# ATmega32C1 device description
Architecture: AVR8; Family: megaAVR
Registers are 8-bit, access not given, no defined reset value unless marked. A register's access mark holds for its fields unless they carry their own. Offsets are from the block's base; [hi:lo] are bit positions; {n}, {i} and the like mark numbered series.

## ADC — Analog-to-Digital Converter
Instances: ADC 0x00
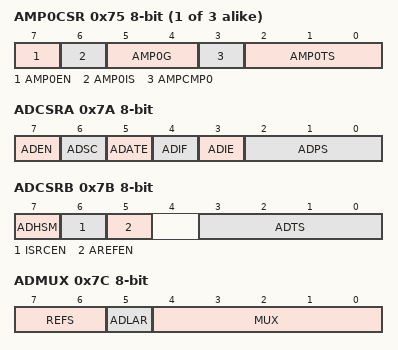
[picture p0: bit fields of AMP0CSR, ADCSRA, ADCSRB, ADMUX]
{0x75+i} AMP{i}CSR (i=0..2)
  [7] AMP{i}EN
  [6] AMP{i}IS
  [5:4] AMP{i}G
  [3] AMPCMP{i} — Amplifier {i} - Comparator {i} Connection
  [2:0] AMP{i}TS
0x78 ADC 16-bit — ADC Data Register Bytes
  [9:0] ADC — ADC Data bits
0x7A ADCSRA — The ADC Control and Status register
  [7] ADEN — ADC Enable
  [6] ADSC — ADC Start Conversion
  [5] ADATE — ADC Auto Trigger Enable
  [4] ADIF — ADC Interrupt Flag
  [3] ADIE — ADC Interrupt Enable
  [2:0] ADPS — ADC Prescaler Select Bits
0x7B ADCSRB — ADC Control and Status Register B
  [7] ADHSM — ADC High Speed Mode
  [6] ISRCEN — Current Source Enable
  [5] AREFEN — Analog Reference pin Enable
  [3:0] ADTS — ADC Auto Trigger Sources
    0=Free Running mode; 1=Analog Comparator; 2=External Interrupt Request 0; 3=Timer/Counter0 Compare Match A; 4=Timer/Counter0 Overflow; 5=Timer/Counter1 Compare Match B; 6=Timer/Counter1 Overflow; 7=Timer/Counter1 Capture Event; 8=PSC0ASY Event; 9=PSC1ASY Event; 10=PSC2ASY Event; 11=Analog comparator 1; 12=Analog comparator 2
0x7C ADMUX — The ADC multiplexer Selection Register
  [7:6] REFS — Reference Selection Bits
    0=AREF, Internal Vref turned off; 1=AVCC with external capacitor at AREF pin; 3=Internal 2.56V Voltage Reference with external capacitor at AREF pin
  [5] ADLAR — Left Adjust Result
  [4:0] MUX — Analog Channel and Gain Selection Bits
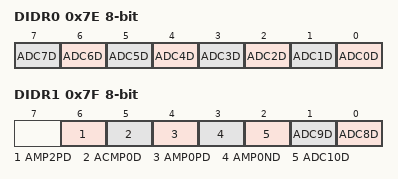
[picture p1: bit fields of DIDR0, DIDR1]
0x7E DIDR0 — Digital Input Disable Register 0
  [n] ADC{n}D (n=0..7) — ADC{n} Digital input Disable
0x7F DIDR1 — Digital Input Disable Register 0
  [6] AMP2PD — AMP2P Pin Digital input Disable
  [5] ACMP0D — ACMP0 Pin Digital input Disable
  [4] AMP0PD — AMP0P Pin Digital input Disable
  [3] AMP0ND — AMP0N Pin Digital input Disable
  [2] ADC10D — ADC10 Pin Digital input Disable
  [1] ADC9D — ADC9 Pin Digital input Disable
  [0] ADC8D — ADC8 Pin Digital input Disable
Value list ANALOG_ADC_MUXPOS: {v}=ADC{v} (ADC input pin {v}) (v=0..10); 11=TEMPSENSE (Temperature sensor); 12=VCC4 (Internal VCC / 4); 13=ISRC (Current source); 14=AMP0 (Analog Differential Amplifier 0); 15=AMP1 (Analog Differential Amplifier 1); 16=AMP2 (Analog Differential Amplifier 2); 17=BNDGAP (Bandgap); 18=GND (0V (GND))

## LINUART — Local Interconnect Network
Instances: LINUART 0x00
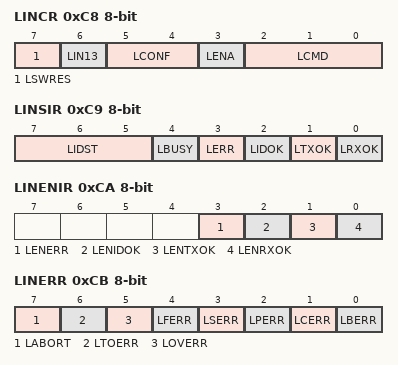
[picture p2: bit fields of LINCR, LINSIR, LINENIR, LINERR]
0xC8 LINCR — LIN Control Register
  [7] LSWRES — Software Reset
  [6] LIN13 — LIN Standard
  [5:4] LCONF — LIN Configuration bits
  [3] LENA — LIN or UART Enable
  [2:0] LCMD — LIN Command and Mode bits
0xC9 LINSIR — LIN Status and Interrupt Register
  [7:5] LIDST — Identifier Status bits
  [4] LBUSY — Busy Signal
  [3] LERR — Error Interrupt
  [2] LIDOK — Identifier Interrupt
  [1] LTXOK — Transmit Performed Interrupt
  [0] LRXOK — Receive Performed Interrupt
0xCA LINENIR — LIN Enable Interrupt Register
  [3] LENERR — Enable Error Interrupt
  [2] LENIDOK — Enable Identifier Interrupt
  [1] LENTXOK — Enable Transmit Performed Interrupt
  [0] LENRXOK — Enable Receive Performed Interrupt
0xCB LINERR — LIN Error Register
  [7] LABORT — Abort Flag
  [6] LTOERR — Frame Time Out Error Flag
  [5] LOVERR — Overrun Error Flag
  [4] LFERR — Framing Error Flag
  [3] LSERR — Synchronization Error Flag
  [2] LPERR — Parity Error Flag
  [1] LCERR — Checksum Error Flag
  [0] LBERR — Bit Error Flag
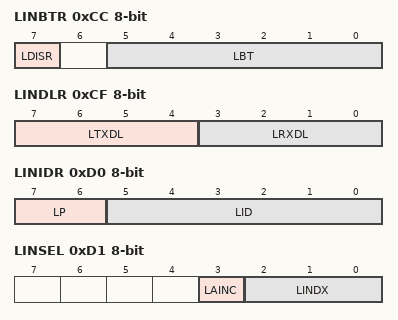
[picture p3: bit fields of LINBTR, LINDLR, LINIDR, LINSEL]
0xCC LINBTR — LIN Bit Timing Register
  [7] LDISR — Disable Bit Timing Resynchronization
  [5:0] LBT — LIN Bit Timing bits
0xCD LINBRR 16-bit — LIN Baud Rate Register
  [11:0] LDIV
0xCF LINDLR — LIN Data Length Register
  [7:4] LTXDL — LIN Transmit Data Length bits
  [3:0] LRXDL — LIN Receive Data Length bits
0xD0 LINIDR — LIN Identifier Register
  [7:6] LP — Parity bits
  [5:0] LID — Identifier bit 5 or Data Length bits
0xD1 LINSEL — LIN Data Buffer Selection Register
  [3] LAINC — Auto Increment of Data Buffer Index (Active Low)
  [2:0] LINDX — FIFO LIN Data Buffer Index bits
0xD2 LINDAT — LIN Data Register
  [7:0] LDATA

## SPI — Serial Peripheral Interface
Instances: SPI 0x00
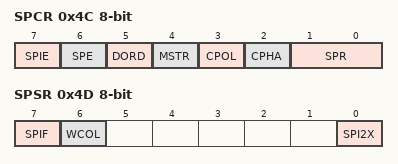
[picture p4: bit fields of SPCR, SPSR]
0x4C SPCR — SPI Control Register
  [7] SPIE — SPI Interrupt Enable
  [6] SPE — SPI Enable
  [5] DORD — Data Order
  [4] MSTR — Master/Slave Select
  [3] CPOL — Clock polarity
  [2] CPHA — Clock Phase
  [1:0] SPR — SPI Clock Rate Selects
    0=fosc/4; 1=fosc/16; 2=fosc/64; 3=fosc/128; 4=fosc/2; 5=fosc/8; 6=fosc/32; 7=fosc/64
0x4D SPSR — SPI Status Register
  [7] SPIF — SPI Interrupt Flag
  [6] WCOL — Write Collision Flag
  [0] SPI2X — Double SPI Speed Bit
0x4E SPDR — SPI Data Register
  [7:0] SPDR — SPI Data bits

## WDT — Watchdog Timer
Instances: WDT 0x00
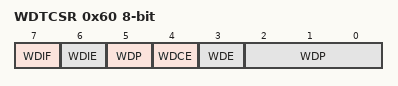
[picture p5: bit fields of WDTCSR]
0x60 WDTCSR — Watchdog Timer Control Register
  [7] WDIF — Watchdog Timeout Interrupt Flag
  [6] WDIE — Watchdog Timeout Interrupt Enable
  [4] WDCE — Watchdog Change Enable
  [3] WDE — Watch Dog Enable
  [5,2:0] WDP — Watchdog Timer Prescaler Bits
    0=Oscillator Cycles 2K; 1=Oscillator Cycles 4K; 2=Oscillator Cycles 8K; 3=Oscillator Cycles 16K; 4=Oscillator Cycles 32K; 5=Oscillator Cycles 64K; 6=Oscillator Cycles 128K; 7=Oscillator Cycles 256K; 8=Oscillator Cycles 512K; 9=Oscillator Cycles 1024K

## EXINT — External Interrupts
Instances: EXINT 0x00
0x3B PCIFR — Pin Change Interrupt Flag Register
  [3:0] PCIF — Pin Change Interrupt Flags
0x3C EIFR — External Interrupt Flag Register
  [3:0] INTF — External Interrupt Flags
0x3D EIMSK — External Interrupt Mask Register
  [3:0] INT — External Interrupt Request 3 Enable
0x68 PCICR — Pin Change Interrupt Control Register
  [3:0] PCIE — Pin Change Interrupt Enables
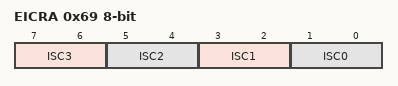
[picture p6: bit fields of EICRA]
0x69 EICRA — External Interrupt Control Register
  [all] fields
    0=Low Level of INTX; 1=Any Logical Change of INTX; 2=Falling Edge of INTX; 3=Rising Edge of INTX
  [7:6] ISC3 — External Interrupt Sense Control Bit
  [5:4] ISC2 — External Interrupt Sense Control Bit
  [3:2] ISC1 — External Interrupt Sense Control 1 Bits
  [1:0] ISC0 — External Interrupt Sense Control 0 Bits
0x6A PCMSK0 — Pin Change Mask Register 0
  [7:0] PCINT — Pin Change Enable Masks
0x6B PCMSK1 — Pin Change Mask Register 1
  [7:0] PCINT (bit 8 of the value upward) — Pin Change Enable Masks
0x6C PCMSK2 — Pin Change Mask Register 2
  [7:0] PCINT (bit 16 of the value upward) — Pin Change Enable Masks
0x6D PCMSK3 — Pin Change Mask Register 3
  [2:0] PCINT (bit 24 of the value upward) — Pin Change Enable Masks

## EEPROM
Instances: EEPROM 0x00
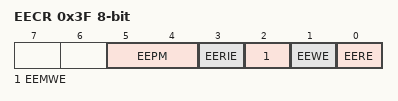
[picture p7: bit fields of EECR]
0x3F EECR — EEPROM Control Register
  [5:4] EEPM — EEPROM Programming mode
    0=Erase and Write in one operation; 1=Erase Only; 2=Write Only
  [3] EERIE — EEPROM Ready Interrupt Enable
  [2] EEMWE — EEPROM Master Write Enable
  [1] EEWE — EEPROM Write Enable
  [0] EERE — EEPROM Read Enable
0x40 EEDR — EEPROM Data Register
  [7:0] EEDR — EEPROM Data bits
0x41 EEAR 16-bit — EEPROM Read/Write Access
  [9:0] EEAR — EEPROM Address bits
